# MSP432E401Y register map
Vendor: Texas Instruments; File version: 3.200
CPU: CM4 r1p2, little endian, no MPU, no FPU, 0x3 interrupt priority bits, 0x0 interrupts
Registers are 32-bit, read-write, no defined reset value unless marked. A register's access mark holds for its fields unless they carry their own. Offsets are from the block's base; [hi:lo] are bit positions; {n}, {i} and the like mark numbered series.

## AES — Register map for AES peripheral
Base 0x44036000; register names take the prefix AES
0x00 KEY2_6 — AES Key 2_6
  [31:0] AES_KEY2_6_KEY — Key Data
0x04 KEY2_7 — AES Key 2_7
  [31:0] AES_KEY2_7_KEY — Key Data
0x08 KEY2_4 — AES Key 2_4
  [31:0] AES_KEY2_4_KEY — Key Data
0x0C KEY2_5 — AES Key 2_5
  [31:0] AES_KEY2_5_KEY — Key Data
0x10 KEY2_2 — AES Key 2_2
  [31:0] AES_KEY2_2_KEY — Key Data
0x14 KEY2_3 — AES Key 2_3
  [31:0] AES_KEY2_3_KEY — Key Data
0x18 KEY2_0 — AES Key 2_0
  [31:0] AES_KEY2_0_KEY — Key Data
0x1C KEY2_1 — AES Key 2_1
  [31:0] AES_KEY2_1_KEY — Key Data
0x20 KEY1_6 — AES Key 1_6
  [31:0] AES_KEY1_6_KEY — Key Data
0x24 KEY1_7 — AES Key 1_7
  [31:0] AES_KEY1_7_KEY — Key Data
0x28 KEY1_4 — AES Key 1_4
  [31:0] AES_KEY1_4_KEY — Key Data
0x2C KEY1_5 — AES Key 1_5
  [31:0] AES_KEY1_5_KEY — Key Data
0x30 KEY1_2 — AES Key 1_2
  [31:0] AES_KEY1_2_KEY — Key Data
0x34 KEY1_3 — AES Key 1_3
  [31:0] AES_KEY1_3_KEY — Key Data
0x38 KEY1_0 — AES Key 1_0
  [31:0] AES_KEY1_0_KEY — Key Data
0x3C KEY1_1 — AES Key 1_1
  [31:0] AES_KEY1_1_KEY — Key Data
{0x40+4i} IV_IN_{i} (i=0..3) — AES Initialization Vector Input {i}
  [31:0] AES_IV_IN_{i}_DATA — Initialization Vector Input
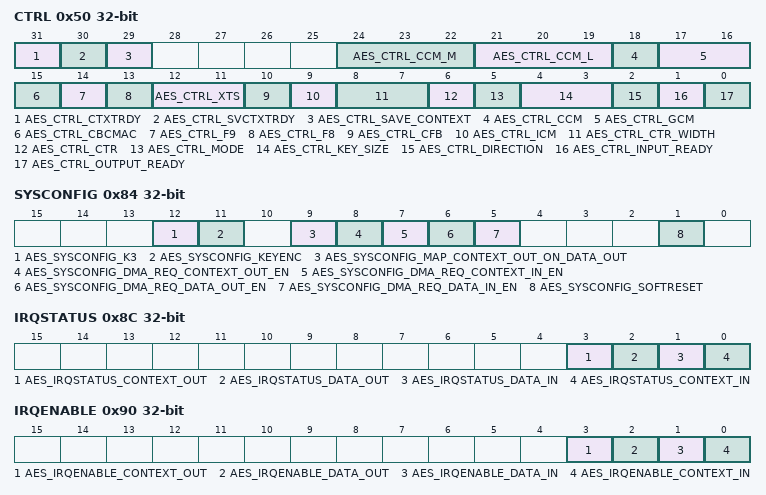
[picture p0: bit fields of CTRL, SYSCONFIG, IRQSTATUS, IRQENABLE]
0x50 CTRL — AES Control
  [31] AES_CTRL_CTXTRDY — Context Data Registers Ready
  [30] AES_CTRL_SVCTXTRDY — AES TAG/IV Block(s) Ready
  [29] AES_CTRL_SAVE_CONTEXT — TAG or Result IV Save
  [24:22] AES_CTRL_CCM_M — Counter with CBC-MAC (CCM)
  [21:19] AES_CTRL_CCM_L — L Value
    1=width = 2; 3=width = 4; 7=width = 8
  [18] AES_CTRL_CCM — AES-CCM Mode Enable
  [17:16] AES_CTRL_GCM — AES-GCM Mode Enable
    0=AES_CTRL_GCM_NOP (No operation); 1=AES_CTRL_GCM_HLY0ZERO (GHASH with H loaded and Y0-encrypted forced to zero); 2=AES_CTRL_GCM_HLY0CALC (GHASH with H loaded and Y0-encrypted calculated internally); 3=AES_CTRL_GCM_HY0CALC (Autonomous GHASH (both H and Y0-encrypted calculated internally))
  [15] AES_CTRL_CBCMAC — AES-CBC MAC Enable
  [14] AES_CTRL_F9 — AES f9 Mode Enable
  [13] AES_CTRL_F8 — AES f8 Mode Enable
  [12:11] AES_CTRL_XTS — AES-XTS Operation Enabled
    0=AES_CTRL_XTS_NOP (No operation); 1=AES_CTRL_XTS_TWEAKJL (Previous/intermediate tweak value and j loaded (value is loaded via IV, j is loaded via the AAD length register)); 2=AES_CTRL_XTS_K2IJL (Key2, n and j are loaded (n is loaded via IV, j is loaded via the AAD length register)); 3=AES_CTRL_XTS_K2ILJ0 (Key2 and n are loaded; j=0 (n is loaded via IV))
  [10] AES_CTRL_CFB — Full block AES cipher feedback mode (CFB128) Enable
  [9] AES_CTRL_ICM — AES Integer Counter Mode (ICM) Enable
  [8:7] AES_CTRL_CTR_WIDTH — AES-CTR Mode Counter Width
    0=Counter is 32 bits; 1=Counter is 64 bits; 2=Counter is 96 bits; 3=Counter is 128 bits
  [6] AES_CTRL_CTR — Counter Mode
  [5] AES_CTRL_MODE — ECB/CBC Mode
  [4:3] AES_CTRL_KEY_SIZE — Key Size
    1=Key is 128 bits; 2=Key is 192 bits; 3=Key is 256 bits
  [2] AES_CTRL_DIRECTION — Encryption/Decryption Selection
  [1] AES_CTRL_INPUT_READY — Input Ready Status
  [0] AES_CTRL_OUTPUT_READY — Output Ready Status
0x54 C_LENGTH_0 — AES Crypto Data Length 0
  [31:0] AES_C_LENGTH_0_LENGTH — Data Length
0x58 C_LENGTH_1 — AES Crypto Data Length 1
  [31:0] AES_C_LENGTH_1_LENGTH — Data Length
0x5C AUTH_LENGTH — AES Authentication Data Length
  [31:0] AES_AUTH_LENGTH_AUTH — Authentication Data Length
{0x60+4i} DATA_IN_{i} (i=0..3) — AES Data RW Plaintext/Ciphertext {i}
  [31:0] AES_DATA_IN_{i}_DATA — Secure Data RW Plaintext/Ciphertext
{0x70+4i} TAG_OUT_{i} (i=0..3) — AES Hash Tag Out {i}
  [31:0] AES_TAG_OUT_{i}_HASH — Hash Result
0x80 REVISION — AES IP Revision Identifier
  [31:0] AES_REVISION — Revision number
0x84 SYSCONFIG — AES System Configuration
  [12] AES_SYSCONFIG_K3 — K3 Select
  [11] AES_SYSCONFIG_KEYENC — Key Encoding
  [9] AES_SYSCONFIG_MAP_CONTEXT_OUT_ON_DATA_OUT — Map Context Out on Data Out Enable
  [8] AES_SYSCONFIG_DMA_REQ_CONTEXT_OUT_EN — DMA Request Context Out Enable
  [7] AES_SYSCONFIG_DMA_REQ_CONTEXT_IN_EN — DMA Request Context In Enable
  [6] AES_SYSCONFIG_DMA_REQ_DATA_OUT_EN — DMA Request Data Out Enable
  [5] AES_SYSCONFIG_DMA_REQ_DATA_IN_EN — DMA Request Data In Enable
  [1] AES_SYSCONFIG_SOFTRESET — Soft reset
0x88 SYSSTATUS — AES System Status
  [0] AES_SYSSTATUS_RESETDONE — Reset Done
0x8C IRQSTATUS — AES Interrupt Status
  [3] AES_IRQSTATUS_CONTEXT_OUT — Context Output Interrupt Status
  [2] AES_IRQSTATUS_DATA_OUT — Data Out Interrupt Status
  [1] AES_IRQSTATUS_DATA_IN — Data In Interrupt Status
  [0] AES_IRQSTATUS_CONTEXT_IN — Context In Interrupt Status
0x90 IRQENABLE — AES Interrupt Enable
  [3] AES_IRQENABLE_CONTEXT_OUT — Context Out Interrupt Enable
  [2] AES_IRQENABLE_DATA_OUT — Data Out Interrupt Enable
  [1] AES_IRQENABLE_DATA_IN — Data In Interrupt Enable
  [0] AES_IRQENABLE_CONTEXT_IN — Context In Interrupt Enable
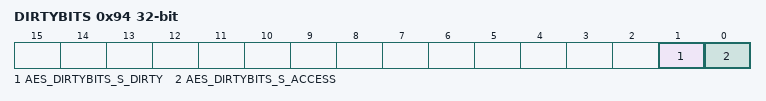
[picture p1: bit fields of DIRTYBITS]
0x94 DIRTYBITS — AES Dirty Bits
  [1] AES_DIRTYBITS_S_DIRTY — AES Dirty Bit
  [0] AES_DIRTYBITS_S_ACCESS — AES Access Bit
